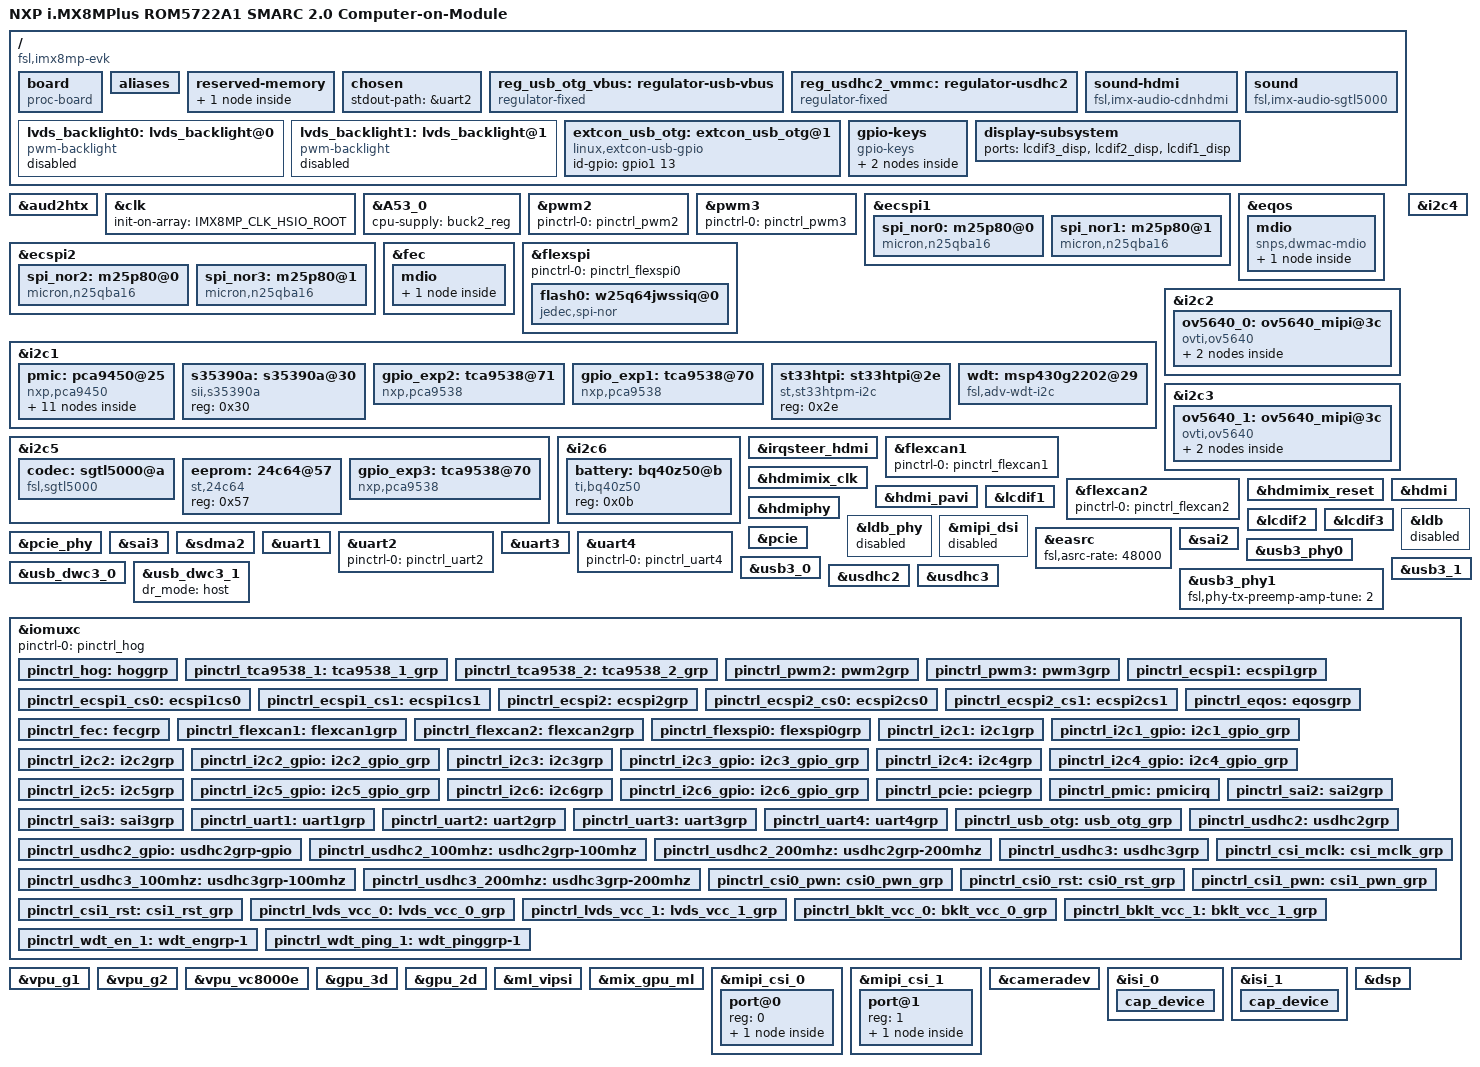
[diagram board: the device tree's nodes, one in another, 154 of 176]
// SPDX-License-Identifier: (GPL-2.0+ OR MIT)
/*
 * Copyright 2019 NXP
 */

/dts-v1/;

#include <dt-bindings/usb/pd.h>
#include "imx8mp.dtsi"

/* Definitions */
#define ROM_DB5901
#define ROM_DB5901_I2S_CN3

/ {
	model = "NXP i.MX8MPlus ROM5722A1 SMARC 2.0 Computer-on-Module";
	compatible = "fsl,imx8mp-evk", "fsl,imx8mp";

	board {
		compatible = "proc-board";
		board-type = "ROM-5722 A1";
		board-cpu = "IMX8MP";
	};

	aliases {
		rtc0 = &s35390a;
		rtc1 = &snvs_rtc;
	};

	reserved-memory {
		#address-cells = <2>;
		#size-cells = <2>;
		ranges;

		rpmsg_reserved: rpmsg@0x55800000 {
			no-map;
			reg = <0 0x55800000 0 0x800000>;
		};
	};

	chosen {
		stdout-path = &uart2;
	};

	reg_usb_otg_vbus: regulator-usb-vbus {
		compatible = "regulator-fixed";
		regulator-name = "usb_otg_vbus";
		regulator-min-microvolt = <5000000>;
		regulator-max-microvolt = <5000000>;
		gpio = <&gpio1 12 GPIO_ACTIVE_HIGH>;
		enable-active-high;
		regulator-always-on;
	};

	reg_usdhc2_vmmc: regulator-usdhc2 {
		compatible = "regulator-fixed";
		regulator-name = "VSD_3V3";
		regulator-min-microvolt = <3300000>;
		regulator-max-microvolt = <3300000>;
		gpio = <&gpio2 19 GPIO_ACTIVE_HIGH>;
		enable-active-high;
		startup-delay-us = <100>;
		off-on-delay-us = <12000>;
	};

	sound-hdmi {
		compatible = "fsl,imx-audio-cdnhdmi";
		model = "audio-hdmi";
		audio-cpu = <&aud2htx>;
		hdmi-out;
		constraint-rate = <44100>,
				<88200>,
				<176400>,
				<32000>,
				<48000>,
				<96000>,
				<192000>;
		status = "okay";
	};

	lvds_backlight0: lvds_backlight@0 {
		compatible = "pwm-backlight";
		pwms = <&pwm2 0 5000000>;
		status = "disabled";

		brightness-levels = < 0  1  2  3  4  5  6  7  8  9
				     10 11 12 13 14 15 16 17 18 19
				     20 21 22 23 24 25 26 27 28 29
				     30 31 32 33 34 35 36 37 38 39
				     40 41 42 43 44 45 46 47 48 49
				     50 51 52 53 54 55 56 57 58 59
				     60 61 62 63 64 65 66 67 68 69
				     70 71 72 73 74 75 76 77 78 79
				     80 81 82 83 84 85 86 87 88 89
				     90 91 92 93 94 95 96 97 98 99
				    100>;
		default-brightness-level = <80>;
	};

	lvds_backlight1: lvds_backlight@1 {
		compatible = "pwm-backlight";
		pwms = <&pwm3 0 5000000>;
		status = "disabled";

		brightness-levels = < 0  1  2  3  4  5  6  7  8  9
				     10 11 12 13 14 15 16 17 18 19
				     20 21 22 23 24 25 26 27 28 29
				     30 31 32 33 34 35 36 37 38 39
				     40 41 42 43 44 45 46 47 48 49
				     50 51 52 53 54 55 56 57 58 59
				     60 61 62 63 64 65 66 67 68 69
				     70 71 72 73 74 75 76 77 78 79
				     80 81 82 83 84 85 86 87 88 89
				     90 91 92 93 94 95 96 97 98 99
				    100>;
		default-brightness-level = <80>;
	};

#ifdef ROM_DB5901
	sound: sound {
		compatible = "fsl,imx-audio-sgtl5000";
		model = "sgtl50000";
#ifdef ROM_DB5901_I2S_CN3
		ssi-controller = <&sai3>;
#else
		ssi-controller = <&sai2>;
#endif
		audio-codec = <&codec>;
		no-audmux;
		audio-routing =
			"MIC_IN", "Mic Jack",
			"Mic Jack", "Mic Bias",
			"Headphone Jack", "HP_OUT";
	};
#endif

	extcon_usb_otg: extcon_usb_otg@1 {
		compatible = "linux,extcon-usb-gpio";
		id-gpio = <&gpio1 13 GPIO_ACTIVE_HIGH>;
	};

	gpio-keys {
		compatible = "gpio-keys";
		#address-cells = <1>;
		#size-cells = <0>;
		pinctrl-names = "default";

		lid@1 {
			label = "LID KEY";
			gpios = <&gpio_exp1 6 GPIO_ACTIVE_HIGH>;
			linux,input-type = <EV_PWR>; //EV_KEY 1, EV_PWR 22
			linux,code = <KEY_SUSPEND>; //KEY_SUSPEND 205, KEY_SLEEP 142, KEY_POWER 116
			wakeup-source;
			debounce-interval = <100>;
		};

		sleep@2 {
			label = "SLEEP KEY";
			gpios = <&gpio_exp1 7 GPIO_ACTIVE_HIGH>;
			linux,input-type = <EV_PWR>; //EV_KEY 1, EV_PWR 22
			linux,code = <KEY_SLEEP>; //KEY_SUSPEND 205, KEY_SLEEP 142, KEY_POWER 116
			wakeup-source;
			debounce-interval = <100>;
		};
	};

	display-subsystem {
		ports = <&lcdif3_disp>,
			<&lcdif2_disp>,
			<&lcdif1_disp>;
	};
};

&aud2htx {
	status = "okay";
};

&clk {
	init-on-array = <IMX8MP_CLK_HSIO_ROOT>;
};

&A53_0 {
	cpu-supply = <&buck2_reg>;
};

&pwm2 {
	pinctrl-names = "default";
	pinctrl-0 = <&pinctrl_pwm2>;
	status = "okay";
};

&pwm3 {
	pinctrl-names = "default";
	pinctrl-0 = <&pinctrl_pwm3>;
	status = "okay";
};

&ecspi1 {
	#address-cells = <1>;
	#size-cells = <0>;
	fsl,spi-num-chipselects = <2>;
	pinctrl-names = "default";
	pinctrl-0 = <&pinctrl_ecspi1 &pinctrl_ecspi1_cs0 &pinctrl_ecspi1_cs1>;
	cs-gpios = <&gpio5 9 GPIO_ACTIVE_LOW>, <&gpio1 7 GPIO_ACTIVE_LOW>;
	status = "okay";

#ifdef ROM_DB5901
	spi_nor0: m25p80@0 {
		compatible = "micron,n25qba16";
		spi-max-frequency = <10000000>;
		reg = <0>;
	};

	spi_nor1: m25p80@1 {
		compatible = "micron,n25qba16";
		spi-max-frequency = <10000000>;
		reg = <1>;
	};
#endif
};

&ecspi2 {
	#address-cells = <1>;
	#size-cells = <0>;
	fsl,spi-num-chipselects = <2>;
	pinctrl-names = "default";
	pinctrl-0 = <&pinctrl_ecspi2 &pinctrl_ecspi2_cs0 &pinctrl_ecspi2_cs1>;
	cs-gpios = <&gpio5 13 GPIO_ACTIVE_LOW>, <&gpio1 8 GPIO_ACTIVE_LOW>;
	status = "okay";

#ifdef ROM_DB5901
	spi_nor2: m25p80@0 {
		compatible = "micron,n25qba16";
		spi-max-frequency = <10000000>;
		reg = <0>;
	};

	spi_nor3: m25p80@1 {
		compatible = "micron,n25qba16";
		spi-max-frequency = <10000000>;
		reg = <1>;
	};
#endif
};

&eqos {
	pinctrl-names = "default";
	pinctrl-0 = <&pinctrl_eqos>;
	phy-mode = "rgmii-id";
	phy-handle = <&ethphy0>;
	snps,reset-gpios = <&gpio4 22 GPIO_ACTIVE_LOW>;
	snps,reset-delays-us = <10 20 200000>;
	status = "okay";
	
	mdio {
		compatible = "snps,dwmac-mdio";
		#address-cells = <1>;
		#size-cells = <0>;

		ethphy0: ethernet-phy@4 {
			compatible = "ethernet-phy-ieee802.3-c22";
			reg = <4>;
			eee-broken-1000t;
			at803x,eee-disabled;
			at803x,vddio-1p8v;
		};
	};
};

&fec {
	pinctrl-names = "default";
	pinctrl-0 = <&pinctrl_fec>;
	phy-mode = "rgmii-id";
	phy-handle = <&ethphy1>;
	fsl,magic-packet;
	status = "okay";
	
	mdio {
		#address-cells = <1>;
		#size-cells = <0>;
		
		ethphy1: ethernet-phy@4 {
			compatible = "ethernet-phy-ieee802.3-c22";
			reg = <4>;
			at803x,eee-disabled;
			at803x,vddio-1p8v;
		};
	};
};

&flexspi {
	pinctrl-names = "default";
	pinctrl-0 = <&pinctrl_flexspi0>;
	status = "okay";

	flash0: w25q64jwssiq@0 {
		reg = <0>;
		#address-cells = <1>;
		#size-cells = <1>;
		compatible = "jedec,spi-nor", "winbond,w25q64";
		spi-max-frequency = <29000000>;
		spi-tx-bus-width = <4>;
		spi-rx-bus-width = <4>;
	};
};

&i2c1 {
	clock-frequency = <100000>;
	pinctrl-names = "default", "gpio";
	pinctrl-0 = <&pinctrl_i2c1>;
	pinctrl-1 = <&pinctrl_i2c1_gpio>;
	scl-gpios = <&gpio5 14 GPIO_ACTIVE_HIGH>;
	sda-gpios = <&gpio5 15 GPIO_ACTIVE_HIGH>;
	status = "okay";

	pmic: pca9450@25 {
		reg = <0x25>;
		compatible = "nxp,pca9450";
		/* PMIC PCA9450 PMIC_nINT GPIO1_IO3 */
		pinctrl-0 = <&pinctrl_pmic>;
		gpio_intr = <&gpio1 3 GPIO_ACTIVE_LOW>;

		regulators {
			#address-cells = <1>;
			#size-cells = <0>;

			pca9450,pmic-buck2-uses-i2c-dvs;
			/* Run/Standby voltage */
			pca9450,pmic-buck2-dvs-voltage = <950000>, <850000>;

			buck1_reg: regulator@0 {
				reg = <0>;
				regulator-compatible = "buck1";
				regulator-min-microvolt = <600000>;
				regulator-max-microvolt = <2187500>;
				regulator-boot-on;
				regulator-always-on;
				regulator-ramp-delay = <3125>;
			};

			buck2_reg: regulator@1 {
				reg = <1>;
				regulator-compatible = "buck2";
				regulator-min-microvolt = <600000>;
				regulator-max-microvolt = <2187500>;
				regulator-boot-on;
				regulator-always-on;
				regulator-ramp-delay = <3125>;
			};

			buck4_reg: regulator@3 {
				reg = <3>;
				regulator-compatible = "buck4";
				regulator-min-microvolt = <600000>;
				regulator-max-microvolt = <3400000>;
				regulator-boot-on;
				regulator-always-on;
			};

			buck5_reg: regulator@4 {
				reg = <4>;
				regulator-compatible = "buck5";
				regulator-min-microvolt = <600000>;
				regulator-max-microvolt = <3400000>;
				regulator-boot-on;
				regulator-always-on;
			};

			buck6_reg: regulator@5 {
				reg = <5>;
				regulator-compatible = "buck6";
				regulator-min-microvolt = <600000>;
				regulator-max-microvolt = <3400000>;
				regulator-boot-on;
				regulator-always-on;
			};

			ldo1_reg: regulator@6 {
				reg = <6>;
				regulator-compatible = "ldo1";
				regulator-min-microvolt = <1600000>;
				regulator-max-microvolt = <3300000>;
				regulator-boot-on;
				regulator-always-on;
			};

			ldo2_reg: regulator@7 {
				reg = <7>;
				regulator-compatible = "ldo2";
				regulator-min-microvolt = <800000>;
				regulator-max-microvolt = <1150000>;
				regulator-boot-on;
				regulator-always-on;
			};

			ldo3_reg: regulator@8 {
				reg = <8>;
				regulator-compatible = "ldo3";
				regulator-min-microvolt = <800000>;
				regulator-max-microvolt = <3300000>;
				regulator-boot-on;
				regulator-always-on;
			};

			ldo4_reg: regulator@9 {
				reg = <9>;
				regulator-compatible = "ldo4";
				regulator-min-microvolt = <800000>;
				regulator-max-microvolt = <3300000>;
				regulator-boot-on;
				regulator-always-on;
			};

			ldo5_reg: regulator@10 {
				reg = <10>;
				regulator-compatible = "ldo5";
				regulator-min-microvolt = <1800000>;
				regulator-max-microvolt = <3300000>;
			};
		};
	};

	s35390a: s35390a@30 {
		compatible = "sii,s35390a";
		reg = <0x30>;
		status = "okay";
	};

	gpio_exp2: tca9538@71 {
		compatible = "nxp,pca9538";
		reg = <0x71>;
		pinctrl-0 = <&pinctrl_tca9538_2>;
		interrupt-parent = <&gpio4>;
		interrupts = <1 IRQ_TYPE_NONE>;
		gpio-controller;
		#gpio-cells = <2>;
		interrupt-controller;
		#interrupt-cells = <2>;
	};

	gpio_exp1: tca9538@70 {
		compatible = "nxp,pca9538";
		reg = <0x70>;
		pinctrl-0 = <&pinctrl_tca9538_1>;
		interrupt-parent = <&gpio4>;
		interrupts = <0 IRQ_TYPE_NONE>;
		gpio-controller;
		#gpio-cells = <2>;
		interrupt-controller;
		#interrupt-cells = <2>;
	};

	st33htpi: st33htpi@2e {
		compatible = "st,st33htpm-i2c";
		reg = <0x2e>;
		pinctrl-names = "default";
	};

	wdt: msp430g2202@29 {
		compatible = "fsl,adv-wdt-i2c";
		reg = <0x29>;
		pinctrl-names = "default";
		pinctrl-0 = <&pinctrl_wdt_en_1 &pinctrl_wdt_ping_1>;
		wdt-en = <&gpio3 19 0>;
		wdt-ping = <&gpio4 20 0>;
		status = "okay";
	};
};

&i2c2 {
	clock-frequency = <100000>;
	pinctrl-names = "default", "gpio";
	pinctrl-0 = <&pinctrl_i2c2>;
	pinctrl-1 = <&pinctrl_i2c2_gpio>;
	scl-gpios = <&gpio5 16 GPIO_ACTIVE_HIGH>;
	sda-gpios = <&gpio5 17 GPIO_ACTIVE_HIGH>;
	status = "okay";

	ov5640_0: ov5640_mipi@3c {
		compatible = "ovti,ov5640";
		reg = <0x3c>;
		pinctrl-names = "default";
		pinctrl-0 = <&pinctrl_csi1_pwn>, <&pinctrl_csi1_rst>, <&pinctrl_csi_mclk>;
		clocks = <&clk IMX8MP_CLK_IPP_DO_CLKO1>;
		clock-names = "xclk";
		assigned-clocks = <&clk IMX8MP_CLK_IPP_DO_CLKO1>;
		assigned-clock-parents = <&clk IMX8MP_CLK_24M>;
		assigned-clock-rates = <24000000>;
		csi_id = <0>;
		powerdown-gpios = <&gpio4 19 GPIO_ACTIVE_HIGH>;
		reset-gpios = <&gpio4 29 GPIO_ACTIVE_LOW>;
		mclk = <24000000>;
		mclk_source = <0>;
		mipi_csi;
		status = "okay";

		port {
			ov5640_mipi_0_ep: endpoint {
				remote-endpoint = <&mipi_csi0_ep>;
				data-lanes = <1 2>;
				clock-lanes = <0>;
			};
		};
	};
};

&i2c3 {
	clock-frequency = <100000>;
	pinctrl-names = "default", "gpio";
	pinctrl-0 = <&pinctrl_i2c3>;
	pinctrl-1 = <&pinctrl_i2c3_gpio>;
	scl-gpios = <&gpio5 18 GPIO_ACTIVE_HIGH>;
	sda-gpios = <&gpio5 19 GPIO_ACTIVE_HIGH>;
	status = "okay";

	ov5640_1: ov5640_mipi@3c {
		compatible = "ovti,ov5640";
		reg = <0x3c>;
		pinctrl-names = "default";
		pinctrl-0 = <&pinctrl_csi0_pwn>, <&pinctrl_csi0_rst>;
		clocks = <&clk IMX8MP_CLK_IPP_DO_CLKO1>;
		clock-names = "xclk";
		assigned-clocks = <&clk IMX8MP_CLK_IPP_DO_CLKO1>;
		assigned-clock-parents = <&clk IMX8MP_CLK_24M>;
		assigned-clock-rates = <24000000>;
		csi_id = <1>;
		powerdown-gpios = <&gpio4 18 GPIO_ACTIVE_HIGH>;
		reset-gpios = <&gpio4 28 GPIO_ACTIVE_LOW>;
		mclk = <24000000>;
		mclk_source = <0>;
		mipi_csi;
		status = "okay";

		port {
			ov5640_mipi_1_ep: endpoint {
				remote-endpoint = <&mipi_csi1_ep>;
				data-lanes = <1 2>;
				clock-lanes = <0>;
			};
		};
	};
};

&i2c4 {
	clock-frequency = <100000>;
	pinctrl-names = "default", "gpio";
	pinctrl-0 = <&pinctrl_i2c4>;
	pinctrl-1 = <&pinctrl_i2c4_gpio>;
	scl-gpios = <&gpio2 4 GPIO_ACTIVE_HIGH>;
	sda-gpios = <&gpio2 5 GPIO_ACTIVE_HIGH>;
	status = "okay";

	/*24c02@50 {
		compatible = "fsl,24c02";
		reg = <0x50>;
	};*/
};

&i2c5 {
	clock-frequency = <100000>;
	pinctrl-names = "default", "gpio";
	pinctrl-0 = <&pinctrl_i2c5>;
	pinctrl-1 = <&pinctrl_i2c5_gpio>;
	scl-gpios = <&gpio2 0 GPIO_ACTIVE_HIGH>;
	sda-gpios = <&gpio2 1 GPIO_ACTIVE_HIGH>;
	status = "okay";

#ifdef ROM_DB5901
	codec: sgtl5000@a {
		compatible = "fsl,sgtl5000";
		reg = <0x0a>;
		clocks = <&audiomix_clk IMX8MP_CLK_AUDIOMIX_SAI3_MCLK1>;
		clock-names = "mclk";
		pinctrl-names = "default";
	};

	eeprom: 24c64@57 {
		compatible = "st,24c64";
		reg = <0x57>;
	};

	gpio_exp3: tca9538@70 {
		compatible = "nxp,pca9538";
		reg = <0x70>;
		gpio-controller;
		#gpio-cells = <2>;
	};
#endif
};

&i2c6 {
	clock-frequency = <100000>;
	pinctrl-names = "default", "gpio";
	pinctrl-0 = <&pinctrl_i2c6>;
	pinctrl-1 = <&pinctrl_i2c6_gpio>;
	scl-gpios = <&gpio3 28 GPIO_ACTIVE_HIGH>;
	sda-gpios = <&gpio3 20 GPIO_ACTIVE_HIGH>;
	status = "okay";

#ifdef ROM_DB5901
	battery: bq40z50@b {
		compatible = "ti,bq40z50";
		reg = <0x0b>;
		pinctrl-names = "default";
		//pinctrl-0 = <&pinctrl_battery>;
	};
#endif
};

&irqsteer_hdmi {
	status = "okay";
};

&flexcan1 {
	pinctrl-names = "default";
	pinctrl-0 = <&pinctrl_flexcan1>;
	status = "okay";
};

&flexcan2 {
	pinctrl-names = "default";
	pinctrl-0 = <&pinctrl_flexcan2>;
	status = "okay";
};

&hdmimix_clk {
	status = "okay";
};

&hdmimix_reset {
	status = "okay";
};

&hdmi_pavi {
	status = "okay";
};

&hdmi {
	status = "okay";
};

&hdmiphy {
	tx_vl_5c = <0x29>;	//For SI test
	tx_vl_60 = <0x52>;	//For SI test
	status = "okay";
};

&lcdif1 {
	status = "okay";
};

&lcdif2 {
	status = "okay";
};

&lcdif3 {
	status = "okay";

	thres-low  = <1 2>;             /* (FIFO * 1 / 2) */
	thres-high = <3 4>;             /* (FIFO * 3 / 4) */
};

&ldb {
	status = "disabled";
};

&ldb_phy {
	status = "disabled";
};

&mipi_dsi {
	status = "disabled";
};

&easrc {
	fsl,asrc-rate  = <48000>;
	status = "okay";
};

&pcie{
	pinctrl-names = "default";
	pinctrl-0 = <&pinctrl_pcie>;
	//clkreq-gpio = <&gpio5 20 GPIO_ACTIVE_HIGH>;	/* PCIE_CLKREQ#_1V8 */
	//disable-gpio = <&gpio_exp3 0 GPIO_ACTIVE_LOW>; /* W_DISABLE1# */
	reset-gpio = <&gpio1 9 GPIO_ACTIVE_LOW>;	/* PCIE_A_RST#_1V8 */
	ext_osc = <1>;
	clocks = <&clk IMX8MP_CLK_HSIO_AXI_DIV>,
		 <&clk IMX8MP_CLK_PCIE_AUX>,
		 <&clk IMX8MP_CLK_PCIE_PHY>,
		 <&clk IMX8MP_CLK_PCIE_ROOT>;
	clock-names = "pcie", "pcie_aux", "pcie_phy", "pcie_bus";
	assigned-clocks = <&clk IMX8MP_CLK_HSIO_AXI_SRC>,
			  <&clk IMX8MP_CLK_PCIE_AUX>;
	assigned-clock-parents = <&clk IMX8MP_SYS_PLL2_500M>,
				 <&clk IMX8MP_SYS_PLL2_50M>;
	status = "okay";
};

&pcie_phy{
	ext_osc = <1>;
	tx_drv_lvl_ctrl_g1 = <0x38>;    //For SI test
	status = "okay";
};

&sai2 {
	pinctrl-names = "default";
	pinctrl-0 = <&pinctrl_sai2>;
	assigned-clocks = <&clk IMX8MP_CLK_SAI2>;
	assigned-clock-parents = <&clk IMX8MP_AUDIO_PLL1_OUT>;
	assigned-clock-rates = <12288000>;
	clocks = <&audiomix_clk IMX8MP_CLK_AUDIOMIX_SAI2_IPG>, <&clk IMX8MP_CLK_DUMMY>,
		 <&audiomix_clk IMX8MP_CLK_AUDIOMIX_SAI2_MCLK1>, <&clk IMX8MP_CLK_DUMMY>,
		 <&clk IMX8MP_CLK_DUMMY>;
	clock-names = "bus", "mclk0", "mclk1", "mclk2", "mclk3";
	status = "okay";
};

&sai3 {
	pinctrl-names = "default";
	pinctrl-0 = <&pinctrl_sai3>;
	assigned-clocks = <&clk IMX8MP_CLK_SAI3>;
	assigned-clock-parents = <&clk IMX8MP_AUDIO_PLL1_OUT>;
	assigned-clock-rates = <12288000>;
	clocks = <&audiomix_clk IMX8MP_CLK_AUDIOMIX_SAI3_IPG>, <&clk IMX8MP_CLK_DUMMY>,
		 <&audiomix_clk IMX8MP_CLK_AUDIOMIX_SAI3_MCLK1>, <&clk IMX8MP_CLK_DUMMY>,
		 <&clk IMX8MP_CLK_DUMMY>;
	clock-names = "bus", "mclk0", "mclk1", "mclk2", "mclk3";
	fsl,sai-mclk-direction-output;
	status = "okay";
};

&sdma2 {
	status = "okay";
};

&uart1 { /* BT */
	pinctrl-names = "default";
	pinctrl-0 = <&pinctrl_uart1>;
	assigned-clocks = <&clk IMX8MP_CLK_UART1>;
	assigned-clock-parents = <&clk IMX8MP_SYS_PLL1_80M>;
	fsl,uart-has-rtscts;
	status = "okay";
};

&uart2 {
	/* console */
	pinctrl-names = "default";
	pinctrl-0 = <&pinctrl_uart2>;
	status = "okay";
};

&uart3 {
	pinctrl-names = "default";
	pinctrl-0 = <&pinctrl_uart3>;
	assigned-clocks = <&clk IMX8MP_CLK_UART3>;
	assigned-clock-parents = <&clk IMX8MP_SYS_PLL1_80M>;
	fsl,uart-has-rtscts;
	status = "okay";
};

&uart4 {
	pinctrl-names = "default";
	pinctrl-0 = <&pinctrl_uart4>;
	status = "okay";
};

&usb3_phy0 {
	fsl,phy-tx-vref-tune = <6>;
	fsl,phy-tx-rise-tune = <0>;
	fsl,phy-tx-preemp-amp-tune = <3>;
	fsl,phy-comp-dis-tune = <7>;
	fsl,pcs-tx-deemph-3p5db = <0x21>;
	fsl,phy-pcs-tx-swing-full = <0x7f>;
	status = "okay";
};

&usb3_0 {
	status = "okay";
};

&usb_dwc3_0 {
	pinctrl-names = "default";
	pinctrl-0 = <&pinctrl_usb_otg>;
	dr_mode = "otg";
	extcon = <&extcon_usb_otg>;
	vbus-supply = <&reg_usb_otg_vbus>;
	status = "okay";
};

&usb3_phy1 {
	fsl,phy-tx-preemp-amp-tune = <2>;
	status = "okay";
};

&usb3_1 {
	status = "okay";
};

&usb_dwc3_1 {
	dr_mode = "host";
	status = "okay";
};

&usdhc2 {
	pinctrl-names = "default", "state_100mhz", "state_200mhz";
	pinctrl-0 = <&pinctrl_usdhc2>, <&pinctrl_usdhc2_gpio>;
	pinctrl-1 = <&pinctrl_usdhc2_100mhz>, <&pinctrl_usdhc2_gpio>;
	pinctrl-2 = <&pinctrl_usdhc2_200mhz>, <&pinctrl_usdhc2_gpio>;
	cd-gpios = <&gpio2 12 GPIO_ACTIVE_LOW>;
	wp-gpios = <&gpio2 20 GPIO_ACTIVE_HIGH>;
	vmmc-supply = <&reg_usdhc2_vmmc>;
	bus-width = <4>;
	status = "okay";
};

&usdhc3 {
	pinctrl-names = "default", "state_100mhz", "state_200mhz";
	pinctrl-0 = <&pinctrl_usdhc3>;
	pinctrl-1 = <&pinctrl_usdhc3_100mhz>;
	pinctrl-2 = <&pinctrl_usdhc3_200mhz>;
	bus-width = <8>;
	cqe-disabled;
	non-removable;
	status = "okay";
};

&iomuxc {
	pinctrl-names = "default";
	pinctrl-0 = <&pinctrl_hog>;

	pinctrl_hog: hoggrp {
		fsl,pins = <
			MX8MP_IOMUXC_HDMI_DDC_SCL__HDMIMIX_HDMI_SCL	0x400001c3
			MX8MP_IOMUXC_HDMI_DDC_SDA__HDMIMIX_HDMI_SDA	0x400001c3
			MX8MP_IOMUXC_HDMI_HPD__HDMIMIX_HDMI_HPD		0x40000019
			//MX8MP_IOMUXC_SAI1_TXD6__GPIO4_IO18	0x19		/* GPIO0 / CAM0_PWR# */
			//MX8MP_IOMUXC_SAI1_TXD7__GPIO4_IO19	0x19		/* GPIO1 / CAM1_PWR#  */
			//MX8MP_IOMUXC_SAI3_RXFS__GPIO4_IO28	0x19		/* GPIO2 / CAM0_RST# */
			//MX8MP_IOMUXC_SAI3_RXC__GPIO4_IO29	0x19		/* GPIO3 / CAM1_RST# */
			MX8MP_IOMUXC_SAI2_MCLK__GPIO4_IO27	0x19		/* GPIO4 */
			MX8MP_IOMUXC_SPDIF_EXT_CLK__GPIO5_IO05	0x19		/* GPIO5 */
			MX8MP_IOMUXC_UART3_RXD__GPIO5_IO26	0x19		/* GPIO6 */
			MX8MP_IOMUXC_UART3_TXD__GPIO5_IO27	0x19		/* GPIO7 */
		>;
	};

	pinctrl_tca9538_1: tca9538_1_grp {
		fsl,pins = <
			MX8MP_IOMUXC_SAI1_RXFS__GPIO4_IO00	0x1c4	/* I2C_EXP_INT0# */
		>;
	};

	pinctrl_tca9538_2: tca9538_2_grp {
		fsl,pins = <
			MX8MP_IOMUXC_SAI1_RXC__GPIO4_IO01	0x1c4	/* I2C_EXP_INT1# */
		>;
	};

	pinctrl_pwm2: pwm2grp {
		fsl,pins = <
			MX8MP_IOMUXC_SAI5_RXD0__PWM2_OUT	0x116
		>;
	};

	pinctrl_pwm3: pwm3grp {
		fsl,pins = <
			MX8MP_IOMUXC_GPIO1_IO10__PWM3_OUT		0x116
		>;
	};

	pinctrl_ecspi1: ecspi1grp {
		fsl,pins = <
			MX8MP_IOMUXC_ECSPI1_SCLK__ECSPI1_SCLK           0x82
			MX8MP_IOMUXC_ECSPI1_MOSI__ECSPI1_MOSI           0x82
			MX8MP_IOMUXC_ECSPI1_MISO__ECSPI1_MISO           0x82
		>;
	};

	pinctrl_ecspi1_cs0: ecspi1cs0 {
		fsl,pins = <
			MX8MP_IOMUXC_ECSPI1_SS0__GPIO5_IO09             0x19
		>;
	};

	pinctrl_ecspi1_cs1: ecspi1cs1 {
		fsl,pins = <
			MX8MP_IOMUXC_GPIO1_IO07__GPIO1_IO07             0x19
		>;
	};

	pinctrl_ecspi2: ecspi2grp {
		fsl,pins = <
			MX8MP_IOMUXC_ECSPI2_SCLK__ECSPI2_SCLK           0x82
			MX8MP_IOMUXC_ECSPI2_MOSI__ECSPI2_MOSI           0x82
			MX8MP_IOMUXC_ECSPI2_MISO__ECSPI2_MISO           0x82
		>;
	};

	pinctrl_ecspi2_cs0: ecspi2cs0 {
		fsl,pins = <
			MX8MP_IOMUXC_ECSPI2_SS0__GPIO5_IO13             0x19
		>;
	};

	pinctrl_ecspi2_cs1: ecspi2cs1 {
		fsl,pins = <
			MX8MP_IOMUXC_GPIO1_IO08__GPIO1_IO08             0x19
		>;
	};

	pinctrl_eqos: eqosgrp {
		fsl,pins = <
			MX8MP_IOMUXC_ENET_MDC__ENET_QOS_MDC	0x3
			MX8MP_IOMUXC_ENET_MDIO__ENET_QOS_MDIO	0x3
			MX8MP_IOMUXC_ENET_RD0__ENET_QOS_RGMII_RD0	0x91
			MX8MP_IOMUXC_ENET_RD1__ENET_QOS_RGMII_RD1	0x91
			MX8MP_IOMUXC_ENET_RD2__ENET_QOS_RGMII_RD2	0x91
			MX8MP_IOMUXC_ENET_RD3__ENET_QOS_RGMII_RD3	0x91
			MX8MP_IOMUXC_ENET_RXC__CCM_ENET_QOS_CLOCK_GENERATE_RX_CLK	0x91
			MX8MP_IOMUXC_ENET_RX_CTL__ENET_QOS_RGMII_RX_CTL	0x91
			MX8MP_IOMUXC_ENET_TD0__ENET_QOS_RGMII_TD0		0x1f
			MX8MP_IOMUXC_ENET_TD1__ENET_QOS_RGMII_TD1		0x1f
			MX8MP_IOMUXC_ENET_TD2__ENET_QOS_RGMII_TD2		0x1f
			MX8MP_IOMUXC_ENET_TD3__ENET_QOS_RGMII_TD3		0x1f
			MX8MP_IOMUXC_ENET_TX_CTL__ENET_QOS_RGMII_TX_CTL	0x1f
			MX8MP_IOMUXC_ENET_TXC__CCM_ENET_QOS_CLOCK_GENERATE_TX_CLK	0x1f
			MX8MP_IOMUXC_SAI2_RXC__GPIO4_IO22		0x19	/* ENET2_RESET#_IMX */
			MX8MP_IOMUXC_SAI2_RXFS__GPIO4_IO21		0x1c4	/* ENET2_INT# */
		>;
	};

	pinctrl_fec: fecgrp {
		fsl,pins = <
			MX8MP_IOMUXC_SAI1_RXD2__ENET1_MDC		0x3
			MX8MP_IOMUXC_SAI1_RXD3__ENET1_MDIO		0x3
			MX8MP_IOMUXC_SAI1_RXD4__ENET1_RGMII_RD0		0x91
			MX8MP_IOMUXC_SAI1_RXD5__ENET1_RGMII_RD1		0x91
			MX8MP_IOMUXC_SAI1_RXD6__ENET1_RGMII_RD2		0x91
			MX8MP_IOMUXC_SAI1_RXD7__ENET1_RGMII_RD3		0x91
			MX8MP_IOMUXC_SAI1_TXC__ENET1_RGMII_RXC		0x91
			MX8MP_IOMUXC_SAI1_TXFS__ENET1_RGMII_RX_CTL	0x91
			MX8MP_IOMUXC_SAI1_TXD0__ENET1_RGMII_TD0		0x1f
			MX8MP_IOMUXC_SAI1_TXD1__ENET1_RGMII_TD1		0x1f
			MX8MP_IOMUXC_SAI1_TXD2__ENET1_RGMII_TD2		0x1f
			MX8MP_IOMUXC_SAI1_TXD3__ENET1_RGMII_TD3		0x1f
			MX8MP_IOMUXC_SAI1_TXD4__ENET1_RGMII_TX_CTL	0x1f
			MX8MP_IOMUXC_SAI1_TXD5__ENET1_RGMII_TXC		0x1f
			MX8MP_IOMUXC_SAI1_RXD0__GPIO4_IO02		0x19	/* ENET1_RESET#_IMX */
			MX8MP_IOMUXC_SAI1_RXD1__GPIO4_IO03		0x1c4	/* ENET1_INT# */
		>;
	};

	pinctrl_flexcan1: flexcan1grp {
		fsl,pins = <
			MX8MP_IOMUXC_SPDIF_RX__CAN1_RX          0x154
			MX8MP_IOMUXC_SPDIF_TX__CAN1_TX          0x154
		>;
	};

	pinctrl_flexcan2: flexcan2grp {
		fsl,pins = <
			MX8MP_IOMUXC_SAI5_MCLK__CAN2_RX		0x154
			MX8MP_IOMUXC_SAI5_RXD3__CAN2_TX		0x154
		>;
	};

	pinctrl_flexspi0: flexspi0grp {
		fsl,pins = <
			MX8MP_IOMUXC_NAND_ALE__FLEXSPI_A_SCLK		0x1c2
			MX8MP_IOMUXC_NAND_CE0_B__FLEXSPI_A_SS0_B	0x82
			MX8MP_IOMUXC_NAND_DATA00__FLEXSPI_A_DATA00	0x82
			MX8MP_IOMUXC_NAND_DATA01__FLEXSPI_A_DATA01	0x82
			MX8MP_IOMUXC_NAND_DATA02__FLEXSPI_A_DATA02	0x82
			MX8MP_IOMUXC_NAND_DATA03__FLEXSPI_A_DATA03	0x82
		>;
	};

	pinctrl_i2c1: i2c1grp {
		fsl,pins = <
			MX8MP_IOMUXC_I2C1_SCL__I2C1_SCL		0x400001c3
			MX8MP_IOMUXC_I2C1_SDA__I2C1_SDA		0x400001c3
		>;
	};

	pinctrl_i2c1_gpio: i2c1_gpio_grp  {
		fsl,pins = <
			MX8MP_IOMUXC_I2C1_SCL__GPIO5_IO14		0x19
			MX8MP_IOMUXC_I2C1_SDA__GPIO5_IO15		0x19
		>;
	};

	pinctrl_i2c2: i2c2grp {
		fsl,pins = <
			MX8MP_IOMUXC_I2C2_SCL__I2C2_SCL			0x400001c3
			MX8MP_IOMUXC_I2C2_SDA__I2C2_SDA			0x400001c3
		>;
	};

	pinctrl_i2c2_gpio: i2c2_gpio_grp  {
		fsl,pins = <
			MX8MP_IOMUXC_I2C2_SCL__GPIO5_IO16		0x19
			MX8MP_IOMUXC_I2C2_SDA__GPIO5_IO17		0x19
		>;
	};

	pinctrl_i2c3: i2c3grp {
		fsl,pins = <
			MX8MP_IOMUXC_I2C3_SCL__I2C3_SCL			0x400001c3
			MX8MP_IOMUXC_I2C3_SDA__I2C3_SDA			0x400001c3
		>;
	};

	pinctrl_i2c3_gpio: i2c3_gpio_grp  {
		fsl,pins = <
			MX8MP_IOMUXC_I2C3_SCL__GPIO5_IO18		0x19
			MX8MP_IOMUXC_I2C3_SDA__GPIO5_IO19		0x19
		>;
	};

	pinctrl_i2c4: i2c4grp {
		fsl,pins = <
			MX8MP_IOMUXC_SD1_DATA2__I2C4_SCL			0x400001c3
			MX8MP_IOMUXC_SD1_DATA3__I2C4_SDA			0x400001c3
		>;
	};

	pinctrl_i2c4_gpio: i2c4_gpio_grp  {
		fsl,pins = <
			MX8MP_IOMUXC_SD1_DATA2__GPIO2_IO04		0x19
			MX8MP_IOMUXC_SD1_DATA3__GPIO2_IO05		0x19
		>;
	};

	pinctrl_i2c5: i2c5grp {
		fsl,pins = <
			MX8MP_IOMUXC_SD1_CLK__I2C5_SCL			0x400001c3
			MX8MP_IOMUXC_SD1_CMD__I2C5_SDA			0x400001c3
		>;
	};

	pinctrl_i2c5_gpio: i2c5_gpio_grp  {
		fsl,pins = <
			MX8MP_IOMUXC_SD1_CLK__GPIO2_IO00		0x19
			MX8MP_IOMUXC_SD1_CMD__GPIO2_IO01		0x19
		>;
	};

	pinctrl_i2c6: i2c6grp {
		fsl,pins = <
			MX8MP_IOMUXC_HDMI_CEC__I2C6_SCL			0x400001c3
			MX8MP_IOMUXC_SAI5_RXC__I2C6_SDA			0x400001c3
		>;
	};

	pinctrl_i2c6_gpio: i2c6_gpio_grp  {
		fsl,pins = <
			MX8MP_IOMUXC_HDMI_CEC__GPIO3_IO28		0x19
			MX8MP_IOMUXC_SAI5_RXC__GPIO3_IO20		0x19
		>;
	};

	pinctrl_pcie: pciegrp {
		fsl,pins = <
			MX8MP_IOMUXC_I2C4_SCL__PCIE_CLKREQ_B		0x61 	/* PCIE_CLKREQ#_1V8 */
			MX8MP_IOMUXC_I2C4_SDA__GPIO5_IO21		0x41		/* PCIE_WAKE#_1V8 */
			MX8MP_IOMUXC_GPIO1_IO09__GPIO1_IO09		0x41		/* PCIE_A_RST#_1V8 */
		>;
	};

	pinctrl_pmic: pmicirq {
		fsl,pins = <
			MX8MP_IOMUXC_GPIO1_IO03__GPIO1_IO03	0x41
		>;
	};

	pinctrl_sai2: sai2grp {
		fsl,pins = <
			MX8MP_IOMUXC_SAI2_TXFS__AUDIOMIX_SAI2_TX_SYNC	0xd6
			MX8MP_IOMUXC_SAI2_TXC__AUDIOMIX_SAI2_TX_BCLK	0xd6
			MX8MP_IOMUXC_SAI2_RXD0__AUDIOMIX_SAI2_RX_DATA00	0xd6
			MX8MP_IOMUXC_SAI2_TXD0__AUDIOMIX_SAI2_TX_DATA00	0xd6
		>;
	};

	pinctrl_sai3: sai3grp {
		fsl,pins = <
			MX8MP_IOMUXC_SAI3_TXFS__AUDIOMIX_SAI3_TX_SYNC	0xd6
			MX8MP_IOMUXC_SAI3_TXC__AUDIOMIX_SAI3_TX_BCLK	0xd6
			MX8MP_IOMUXC_SAI3_RXD__AUDIOMIX_SAI3_RX_DATA00	0xd6
			MX8MP_IOMUXC_SAI3_TXD__AUDIOMIX_SAI3_TX_DATA00	0xd6
			MX8MP_IOMUXC_SAI3_MCLK__AUDIOMIX_SAI3_MCLK	0xd6
		>;
	};

	pinctrl_uart1: uart1grp {
		fsl,pins = <
			MX8MP_IOMUXC_UART1_RXD__UART1_DCE_RX	0x140
			MX8MP_IOMUXC_UART1_TXD__UART1_DCE_TX	0x140
			MX8MP_IOMUXC_SD1_DATA0__UART1_DCE_RTS	0x140
			MX8MP_IOMUXC_SD1_DATA1__UART1_DCE_CTS	0x140
		>;
	};

	pinctrl_uart2: uart2grp {
		fsl,pins = <
			MX8MP_IOMUXC_UART2_RXD__UART2_DCE_RX	0x49
			MX8MP_IOMUXC_UART2_TXD__UART2_DCE_TX	0x49
		>;
	};

	pinctrl_uart3: uart3grp {
		fsl,pins = <
			MX8MP_IOMUXC_SD1_DATA7__UART3_DCE_RX		0x140
			MX8MP_IOMUXC_SD1_DATA6__UART3_DCE_TX		0x140
			MX8MP_IOMUXC_SD1_RESET_B__UART3_DCE_RTS		0x140
			MX8MP_IOMUXC_SD1_STROBE__UART3_DCE_CTS		0x140
		>;
	};

	pinctrl_uart4: uart4grp {
		fsl,pins = <
			MX8MP_IOMUXC_UART4_RXD__UART4_DCE_RX	0x49
			MX8MP_IOMUXC_UART4_TXD__UART4_DCE_TX	0x49
		>;
	};

	pinctrl_usb_otg: usb_otg_grp {
		fsl,pins = <
			MX8MP_IOMUXC_GPIO1_IO13__GPIO1_IO13     0x19
			MX8MP_IOMUXC_GPIO1_IO12__GPIO1_IO12     0x19
		>;
	};

	pinctrl_usdhc2_gpio: usdhc2grp-gpio {
		fsl,pins = <
			MX8MP_IOMUXC_SD2_CD_B__GPIO2_IO12 	0x1c4
			MX8MP_IOMUXC_SD2_RESET_B__GPIO2_IO19	0x41
			MX8MP_IOMUXC_SD2_WP__GPIO2_IO20	0x41
		>;
	};

	pinctrl_usdhc2: usdhc2grp {
		fsl,pins = <
			MX8MP_IOMUXC_SD2_CLK__USDHC2_CLK	0x190
			MX8MP_IOMUXC_SD2_CMD__USDHC2_CMD	0x1d0
			MX8MP_IOMUXC_SD2_DATA0__USDHC2_DATA0	0x1d0
			MX8MP_IOMUXC_SD2_DATA1__USDHC2_DATA1	0x1d0
			MX8MP_IOMUXC_SD2_DATA2__USDHC2_DATA2	0x1d0
			MX8MP_IOMUXC_SD2_DATA3__USDHC2_DATA3	0x1d0
			MX8MP_IOMUXC_GPIO1_IO04__USDHC2_VSELECT	0xc1
		>;
	};

	pinctrl_usdhc2_100mhz: usdhc2grp-100mhz {
		fsl,pins = <
			MX8MP_IOMUXC_SD2_CLK__USDHC2_CLK	0x194
			MX8MP_IOMUXC_SD2_CMD__USDHC2_CMD	0x1d4
			MX8MP_IOMUXC_SD2_DATA0__USDHC2_DATA0	0x1d4
			MX8MP_IOMUXC_SD2_DATA1__USDHC2_DATA1	0x1d4
			MX8MP_IOMUXC_SD2_DATA2__USDHC2_DATA2	0x1d4
			MX8MP_IOMUXC_SD2_DATA3__USDHC2_DATA3	0x1d4
			MX8MP_IOMUXC_GPIO1_IO04__USDHC2_VSELECT 0xc1
		>;
	};

	pinctrl_usdhc2_200mhz: usdhc2grp-200mhz {
		fsl,pins = <
			MX8MP_IOMUXC_SD2_CLK__USDHC2_CLK	0x196
			MX8MP_IOMUXC_SD2_CMD__USDHC2_CMD	0x1d6
			MX8MP_IOMUXC_SD2_DATA0__USDHC2_DATA0	0x1d6
			MX8MP_IOMUXC_SD2_DATA1__USDHC2_DATA1	0x1d6
			MX8MP_IOMUXC_SD2_DATA2__USDHC2_DATA2	0x1d6
			MX8MP_IOMUXC_SD2_DATA3__USDHC2_DATA3	0x1d6
			MX8MP_IOMUXC_GPIO1_IO04__USDHC2_VSELECT 0xc1
		>;
	};

	pinctrl_usdhc3: usdhc3grp {
		fsl,pins = <
			MX8MP_IOMUXC_NAND_WE_B__USDHC3_CLK	0x190
			MX8MP_IOMUXC_NAND_WP_B__USDHC3_CMD	0x1d0
			MX8MP_IOMUXC_NAND_DATA04__USDHC3_DATA0	0x1d0
			MX8MP_IOMUXC_NAND_DATA05__USDHC3_DATA1	0x1d0
			MX8MP_IOMUXC_NAND_DATA06__USDHC3_DATA2	0x1d0
			MX8MP_IOMUXC_NAND_DATA07__USDHC3_DATA3	0x1d0
			MX8MP_IOMUXC_NAND_RE_B__USDHC3_DATA4	0x1d0
			MX8MP_IOMUXC_NAND_CE2_B__USDHC3_DATA5	0x1d0
			MX8MP_IOMUXC_NAND_CE3_B__USDHC3_DATA6	0x1d0
			MX8MP_IOMUXC_NAND_CLE__USDHC3_DATA7	0x1d0
			MX8MP_IOMUXC_NAND_CE1_B__USDHC3_STROBE	0x190
		>;
	};

	pinctrl_usdhc3_100mhz: usdhc3grp-100mhz {
		fsl,pins = <
			MX8MP_IOMUXC_NAND_WE_B__USDHC3_CLK	0x194
			MX8MP_IOMUXC_NAND_WP_B__USDHC3_CMD	0x1d4
			MX8MP_IOMUXC_NAND_DATA04__USDHC3_DATA0	0x1d4
			MX8MP_IOMUXC_NAND_DATA05__USDHC3_DATA1	0x1d4
			MX8MP_IOMUXC_NAND_DATA06__USDHC3_DATA2	0x1d4
			MX8MP_IOMUXC_NAND_DATA07__USDHC3_DATA3	0x1d4
			MX8MP_IOMUXC_NAND_RE_B__USDHC3_DATA4	0x1d4
			MX8MP_IOMUXC_NAND_CE2_B__USDHC3_DATA5	0x1d4
			MX8MP_IOMUXC_NAND_CE3_B__USDHC3_DATA6	0x1d4
			MX8MP_IOMUXC_NAND_CLE__USDHC3_DATA7	0x1d4
			MX8MP_IOMUXC_NAND_CE1_B__USDHC3_STROBE	0x194
		>;
	};

	pinctrl_usdhc3_200mhz: usdhc3grp-200mhz {
		fsl,pins = <
			MX8MP_IOMUXC_NAND_WE_B__USDHC3_CLK	0x196
			MX8MP_IOMUXC_NAND_WP_B__USDHC3_CMD	0x1d6
			MX8MP_IOMUXC_NAND_DATA04__USDHC3_DATA0	0x1d6
			MX8MP_IOMUXC_NAND_DATA05__USDHC3_DATA1	0x1d6
			MX8MP_IOMUXC_NAND_DATA06__USDHC3_DATA2	0x1d6
			MX8MP_IOMUXC_NAND_DATA07__USDHC3_DATA3	0x1d6
			MX8MP_IOMUXC_NAND_RE_B__USDHC3_DATA4	0x1d6
			MX8MP_IOMUXC_NAND_CE2_B__USDHC3_DATA5	0x1d6
			MX8MP_IOMUXC_NAND_CE3_B__USDHC3_DATA6	0x1d6
			MX8MP_IOMUXC_NAND_CLE__USDHC3_DATA7	0x1d6
			MX8MP_IOMUXC_NAND_CE1_B__USDHC3_STROBE	0x196
		>;
	};

	/*pinctrl_wdog: wdoggrp {
		fsl,pins = <
			MX8MP_IOMUXC_GPIO1_IO02__WDOG1_WDOG_B	0xc6
		>;
	};*/

	pinctrl_csi_mclk: csi_mclk_grp {
		fsl,pins = <
			MX8MP_IOMUXC_GPIO1_IO14__CCM_CLKO1	0x59
		>;
	};

	pinctrl_csi0_pwn: csi0_pwn_grp {
		fsl,pins = <
			MX8MP_IOMUXC_SAI1_TXD6__GPIO4_IO18	0x19		/* GPIO0 / CAM0_PWR# */
		>;
	};

	pinctrl_csi0_rst: csi0_rst_grp {
		fsl,pins = <
			MX8MP_IOMUXC_SAI3_RXFS__GPIO4_IO28		0x19		/* GPIO2 / CAM0_RST# */
		>;
	};

	pinctrl_csi1_pwn: csi1_pwn_grp {
		fsl,pins = <
			MX8MP_IOMUXC_SAI1_TXD7__GPIO4_IO19	0x19		/* GPIO1 / CAM1_PWR#  */
		>;
	};

	pinctrl_csi1_rst: csi1_rst_grp {
		fsl,pins = <
			MX8MP_IOMUXC_SAI3_RXC__GPIO4_IO29		0x19		/* GPIO3 / CAM1_RST# */
		>;
	};

	pinctrl_lvds_vcc_0: lvds_vcc_0_grp {
		fsl,pins = <
			MX8MP_IOMUXC_GPIO1_IO06__GPIO1_IO06	0x19	/* LCD0_VDD_EN */
		>;
	};

	pinctrl_lvds_vcc_1: lvds_vcc_1_grp {
		fsl,pins = <
			MX8MP_IOMUXC_GPIO1_IO05__GPIO1_IO05	0x19	/* LCD1_VDD_EN */
		>;
	};

	pinctrl_bklt_vcc_0: bklt_vcc_0_grp {
		fsl,pins = <
			MX8MP_IOMUXC_GPIO1_IO00__GPIO1_IO00	0x19	/* LCD0_BKLT_EN */
		>;
	};

	pinctrl_bklt_vcc_1: bklt_vcc_1_grp {
		fsl,pins = <
			MX8MP_IOMUXC_GPIO1_IO01__GPIO1_IO01	0x19	/* LCD1_BKLT_EN */
		>;
	};

	pinctrl_wdt_en_1: wdt_engrp-1 {
		fsl,pins = <
			MX8MP_IOMUXC_SAI5_RXFS__GPIO3_IO19      0x19    /* WDT_EN_1V8 */
		>;
	};

	pinctrl_wdt_ping_1: wdt_pinggrp-1 {
		fsl,pins = <
			MX8MP_IOMUXC_SAI1_MCLK__GPIO4_IO20      0x19    /* WDT_TRIG_1V8 */
		>;
	};
};

&vpu_g1 {
	status = "okay";
};

&vpu_g2 {
	status = "okay";
};

&vpu_vc8000e {
	status = "okay";
};

&gpu_3d {
	status = "okay";
};

&gpu_2d {
	status = "okay";
};

&ml_vipsi {
	status = "okay";
};

&mix_gpu_ml {
	status = "okay";
};

&mipi_csi_0 {
	#address-cells = <1>;
	#size-cells = <0>;
	status = "okay";

	port@0 {
		reg = <0>;
		mipi_csi0_ep: endpoint {
			remote-endpoint = <&ov5640_mipi_0_ep>;
			data-lanes = <2>;
			csis-hs-settle = <13>;
			csis-clk-settle = <2>;
			csis-wclk;
		};
	};
};

&mipi_csi_1 {
	#address-cells = <1>;
	#size-cells = <0>;
	status = "okay";

	port@1 {
		reg = <1>;
		mipi_csi1_ep: endpoint {
			remote-endpoint = <&ov5640_mipi_1_ep>;
			data-lanes = <2>;
			csis-hs-settle = <13>;
			csis-clk-settle = <2>;
			csis-wclk;
		};
	};
};

&cameradev {
	status = "okay";
};

&isi_0 {
	status = "okay";

	cap_device {
		status = "okay";
	};
};

&isi_1 {
	status = "okay";

	cap_device {
		status = "okay";
	};
};

&dsp {
	status = "okay";
};
